AUTOSAR XML (schema 00045)
package /FSMonitor
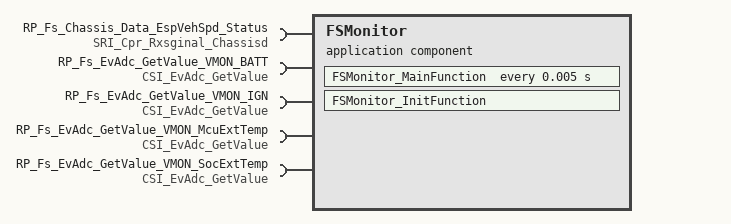
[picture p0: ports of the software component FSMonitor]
  application sw component type FSMonitor  # Function Safety Monitor
    5 x require port:
      RP_Fs_Chassis_Data_EspVehSpd_Status: required-interface=SRI_Cpr_Rxsginal_Chassisd
      RP_Fs_EvAdc_GetValue_VMON_BATT: required-interface=CSI_EvAdc_GetValue
      RP_Fs_EvAdc_GetValue_VMON_IGN: required-interface=CSI_EvAdc_GetValue
      RP_Fs_EvAdc_GetValue_VMON_McuExtTemp: required-interface=CSI_EvAdc_GetValue
      RP_Fs_EvAdc_GetValue_VMON_SocExtTemp: required-interface=CSI_EvAdc_GetValue
    behavior FSMonitor_IB: handle-termination-and-restart=NO-SUPPORT
      init event IE_FSMonitor_InitFunction: start-on-event=FSMonitor_InitFunction
      timing event TE_FSMonitor_MainFunction: start-on-event=FSMonitor_MainFunction, period=0.005
      runnable FSMonitor_InitFunction
      runnable FSMonitor_MainFunction
        data-receive-point-by-arguments:
          access drparg_EspVehSpd: accessed-variable=RP_Fs_Chassis_Data_EspVehSpd_Status.EspVehSpd
        4 x sync call, all with timeout=0.0:
          scp_GetPhyValue: operation=RP_Fs_EvAdc_GetValue_VMON_BATT.GetPhyValue
          scp_GetPhyValue0: operation=RP_Fs_EvAdc_GetValue_VMON_IGN.GetPhyValue
          scp_GetPhyValue1: operation=RP_Fs_EvAdc_GetValue_VMON_McuExtTemp.GetPhyValue
          scp_GetPhyValue2: operation=RP_Fs_EvAdc_GetValue_VMON_SocExtTemp.GetPhyValue
  swc implementation FSMonitor_Impl: programming-language=C, sw-version=1.0.0, vendor-id=0, behavior=FSMonitor_IB
    code-descriptors:
      code CD_FSMonitor: artifact-descriptors=autosar-engineering-object={short-label=SWSRC, category=SWSRC}
    resource consumption Resource
      memory section CODE: sw-addrmethod=CODE
      memory section VAR_UNSPECIFIED: sw-addrmethod=VAR
